# ATSAMA5D26 device description
Architecture: CORTEX-A5; Family: SAMA5D2; Series: SAMA5D2
Registers are 32-bit, read-write, no defined reset value unless marked. A register's access mark holds for its fields unless they carry their own. Offsets are from the block's base; [hi:lo] are bit positions; {n}, {i} and the like mark numbered series; 'fields as' and 'values as' point back to an identical list.

## PDMIC — Pulse Density Modulation Interface Controller
Instances: PDMIC 0xF8018000
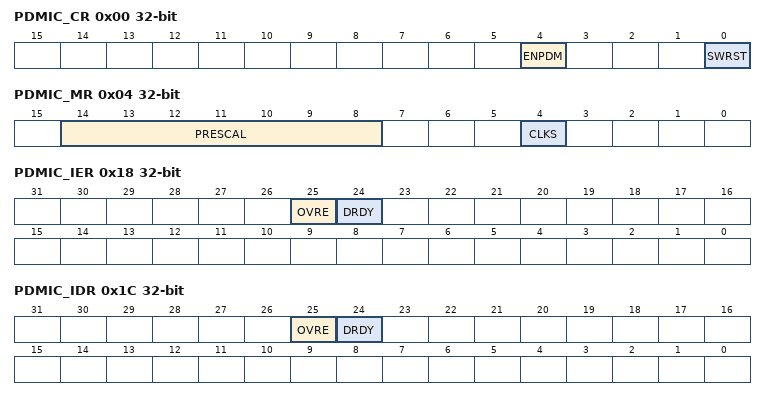
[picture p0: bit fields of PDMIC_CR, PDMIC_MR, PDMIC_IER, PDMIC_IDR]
0x00 PDMIC_CR — Control Register
  [4] ENPDM — Enable PDM
  [0] SWRST — Software Reset
0x04 PDMIC_MR — Mode Register
  [14:8] PRESCAL — Prescaler Rate Selection
  [4] CLKS — Clock Source Selection
0x14 PDMIC_CDR ro — Converted Data Register
  [31:0] DATA — Data Converted
0x18 PDMIC_IER wo — Interrupt Enable Register
  [25] OVRE — Overrun Error Interrupt Enable
  [24] DRDY — Data Ready Interrupt Enable
0x1C PDMIC_IDR wo — Interrupt Disable Register
  [25] OVRE — General Overrun Error Interrupt Disable
  [24] DRDY — Data Ready Interrupt Disable
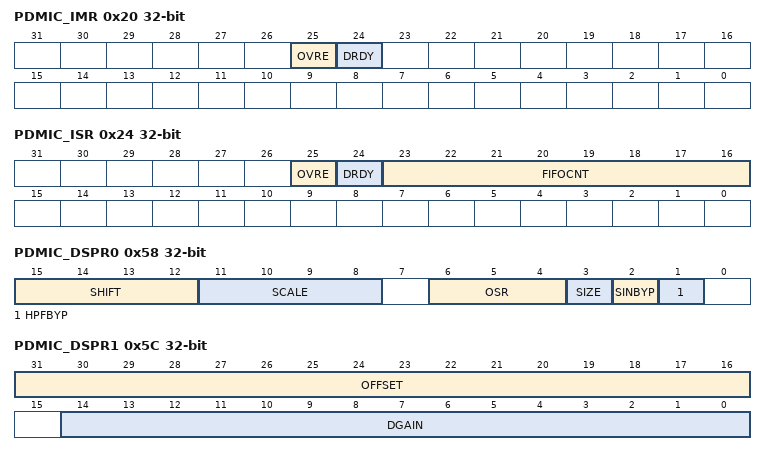
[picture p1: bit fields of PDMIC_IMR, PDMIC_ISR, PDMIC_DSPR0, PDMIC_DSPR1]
0x20 PDMIC_IMR ro — Interrupt Mask Register
  [25] OVRE — General Overrun Error Interrupt Mask
  [24] DRDY — Data Ready Interrupt Mask
0x24 PDMIC_ISR ro — Interrupt Status Register
  [25] OVRE — Overrun Error (cleared on read)
  [24] DRDY — Data Ready (cleared by reading PDMIC_CDR)
  [23:16] FIFOCNT — FIFO Count
0x58 PDMIC_DSPR0 — DSP Configuration Register 0
  [15:12] SHIFT — Data Shift
  [11:8] SCALE — Data Scale
  [6:4] OSR — Global Oversampling Ratio
    0=Global Oversampling ratio is 128 (SINC filter oversampling ratio is 64); 1=Global Oversampling ratio is 64 (SINC filter oversampling ratio is 32)
  [3] SIZE — Data Size
  [2] SINBYP — SINCC Filter Bypass
  [1] HPFBYP — High-Pass Filter Bypass
0x5C PDMIC_DSPR1 — DSP Configuration Register 1
  [31:16] OFFSET — Offset Correction
  [14:0] DGAIN — Gain Correction
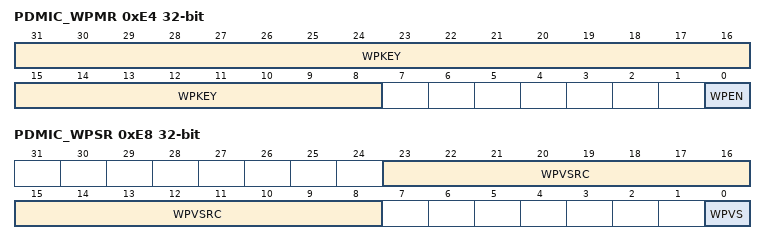
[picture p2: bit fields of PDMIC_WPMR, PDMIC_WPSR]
0xE4 PDMIC_WPMR — Write Protection Mode Register
  [31:8] WPKEY — Write Protection Key
    0x414443=PASSWD (Writing any other value in this field aborts the write operation of the WPEN bit.Always reads as 0.)
  [0] WPEN — Write Protection Enable
0xE8 PDMIC_WPSR ro — Write Protection Status Register
  [23:8] WPVSRC — Write Protection Violation Source
  [0] WPVS — Write Protection Violation Status

## PIO_CTRL — Parallel Input/Output Controller Control
Instances: PIO_CTRL 0xFC038500
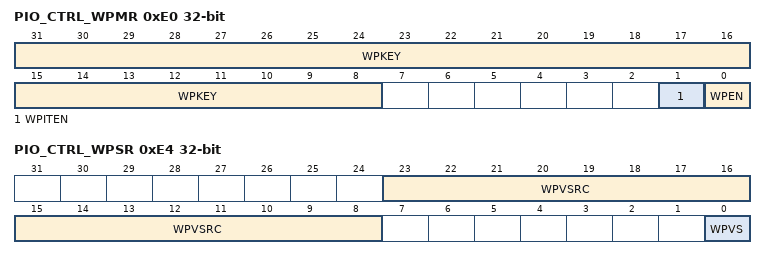
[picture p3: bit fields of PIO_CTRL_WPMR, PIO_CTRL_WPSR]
0xE0 PIO_CTRL_WPMR — PIO Write Protection Mode Register
  [31:8] WPKEY — Write Protection Key
    0x50494F=PASSWD (Writing any other value in this field aborts the write operation of the WPEN bit. Always reads as 0.)
  [1] WPITEN — Write Protection Interrupt Enable
  [0] WPEN — Write Protection Enable
0xE4 PIO_CTRL_WPSR ro — PIO Write Protection Status Register
  [23:8] WPVSRC — Write Protection Violation Source
  [0] WPVS — Write Protection Violation Status

## PIT — Periodic Interval Timer
Instances: PIT 0xF8048030
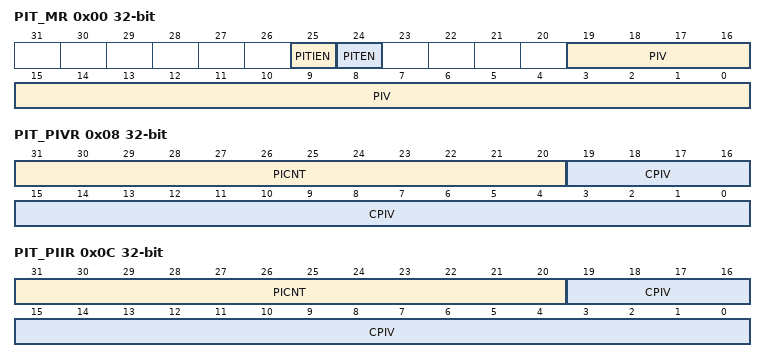
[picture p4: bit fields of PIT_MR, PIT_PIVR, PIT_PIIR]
0x00 PIT_MR — Mode Register
  [25] PITIEN — Periodic Interval Timer Interrupt Enable
  [24] PITEN — Period Interval Timer Enabled
  [19:0] PIV — Periodic Interval Value
0x04 PIT_SR ro — Status Register
  [0] PITS — Periodic Interval Timer Status
0x08 PIT_PIVR ro — Periodic Interval Value Register
  [31:20] PICNT — Periodic Interval Counter
  [19:0] CPIV — Current Periodic Interval Value
0x0C PIT_PIIR ro — Periodic Interval Image Register
  fields as PIT_PIVR

## PTC — Peripheral Touch Controller
Instances: PTC 0xFC060000
0x28 PTC_CMD 8-bit wo — PTC Command Register
  [3:0] CMD — Host Command
    0=NO_ACTION; 1=STOP (Waits for ongoing execution to complete, then stops.); 2=REST (Stops and resets); 4=ABORT (Stops without waiting for ongoing execution to complete.); 5=RUN (Starts execution (from stopped state))
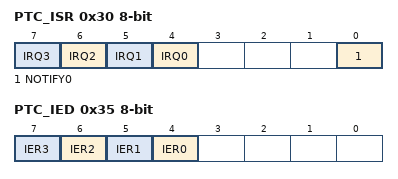
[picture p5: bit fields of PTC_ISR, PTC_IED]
0x30 PTC_ISR 8-bit — PTC Interrupt Status Register
  [n+4] IRQ{n} (n=0..3)
  [0] NOTIFY0 — Notification to the Firmware
0x35 PTC_IED 8-bit wo — PTC Enable Register
  [n+4] IER{n} (n=0..3)

## RSTC — Reset Controller
Instances: RSTC 0xF8048000
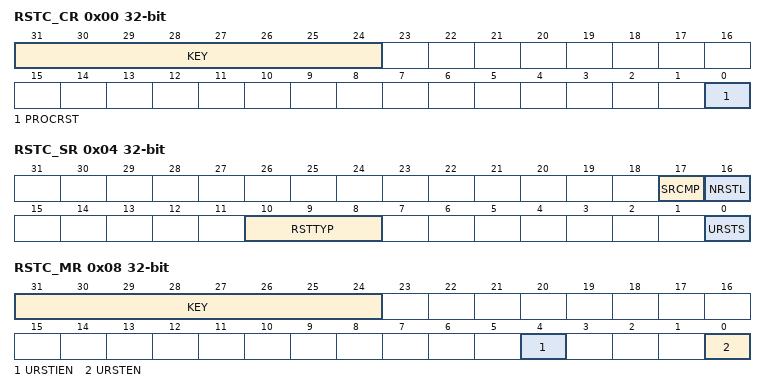
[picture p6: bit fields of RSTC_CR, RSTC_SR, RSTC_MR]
0x00 RSTC_CR wo — Control Register
  [31:24] KEY — Write Access Password
    165=PASSWD (Writing any other value in this field aborts the write operation.Always reads as 0.)
  [0] PROCRST — Processor Reset
0x04 RSTC_SR ro — Status Register
  [17] SRCMP — Software Reset Command in Progress
  [16] NRSTL — NRST Pin Level
  [10:8] RSTTYP — Reset Type
    0=GENERAL_RST (Both VDDCORE and VDDBU rising); 1=WKUP_RST (VDDCORE rising); 2=WDT_RST (Watchdog fault occurred); 3=SOFT_RST (Processor reset required by the software); 4=USER_RST (NRST pin detected low)
  [0] URSTS — User Reset Status
0x08 RSTC_MR — Mode Register
  [31:24] KEY — Write Access Password
    values as RSTC_CR.KEY
  [4] URSTIEN — User Reset Interrupt Enable
  [0] URSTEN — User Reset Enable

## Notices in the file
Copyright (c) 2017 Microchip Technology Inc.
SPDX-License-Identifier: Apache-2.0
Licensed under the Apache License, Version 2.0 (the "License");
you may not use this file except in compliance with the License.
You may obtain a copy of the License at
http://www.apache.org/licenses/LICENSE-2.0
Unless required by applicable law or agreed to in writing, software
distributed under the License is distributed on an "AS IS" BASIS,
WITHOUT WARRANTIES OR CONDITIONS OF ANY KIND, either express or implied.
See the License for the specific language governing permissions and
limitations under the License.
